AUTOSAR XML (schema 00044)
package /ComponentTypes
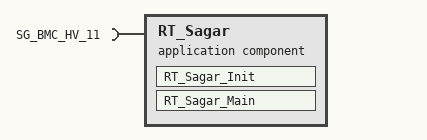
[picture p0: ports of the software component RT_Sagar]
  application sw component type RT_Sagar
    require port SG_BMC_HV_11: nonqueued-receiver-com-spec{data-element=SG_BMC_HV_11, filter=data-filter-type=ALWAYS}, required-interface=SG_BMC_HV_11
    behavior RT_Sagar_InternalBehavior
      init event RT_Sagar_InitEvent: start-on-event=RT_Sagar_Init
      runnable RT_Sagar_Init: minimum-start-interval=5
      runnable RT_Sagar_Main: minimum-start-interval=0.1
        data-receive-point-by-arguments:
          access REC_SG_BMC_HV_11_SG_BMC_HV_11: accessed-variable=SG_BMC_HV_11.SG_BMC_HV_11
  swc implementation RT_Sagar_Implementation: behavior=RT_Sagar_InternalBehavior
